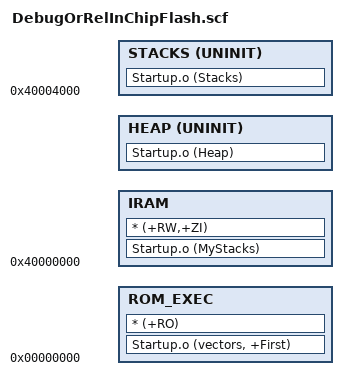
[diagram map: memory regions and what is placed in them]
;/************************************************************************************

;*************************************************************************************/


ROM_LOAD 0x00000000                                ;/* 加载区，从0x00000000开始 */
{
    ROM_EXEC 0x00000000                            ;/* 执行区，起始地址、空间大小要和加载区一致 */
    {
        Startup.o (vectors, +First)                ;/* 存储Startup.s中的向量表（Startup.o为文件Startup.s的目标代码 */
        * (+RO)                                    ;/* 存储其他代码*/
    }
	
   
    IRAM 0x40000000                                ;/* 变量区，从0x40000000处（片内RAM）开始 */                    
    {
        Startup.o (MyStacks)                       ;/* Startup.s中的MyStacks */
        
        * (+RW,+ZI)                                ;/* 文件的其他变量 */
    }

    HEAP +0 UNINIT                                 ;/* 系统堆空间 */
    {
        Startup.o (Heap)                           ;/* Sartup.s中的Heap */
    }

                                                   ;/* 系统栈空间 */
	;// 	STACKS 0x40002000 UNINIT                       ;/* LPC2131片内SRAM(8KB)最高端 */
 	   	STACKS 0x40004000 UNINIT                       ;/* LPC2132/34片内SRAM(16KB)最高端 */
  ;//  	 STACKS 0x40008000 UNINIT                       ;/* LPC2136/38片内SRAM(32KB)最高端 */
    {
        Startup.o (Stacks)                         ;/* Startup.s中的Stacks */
    }
}

